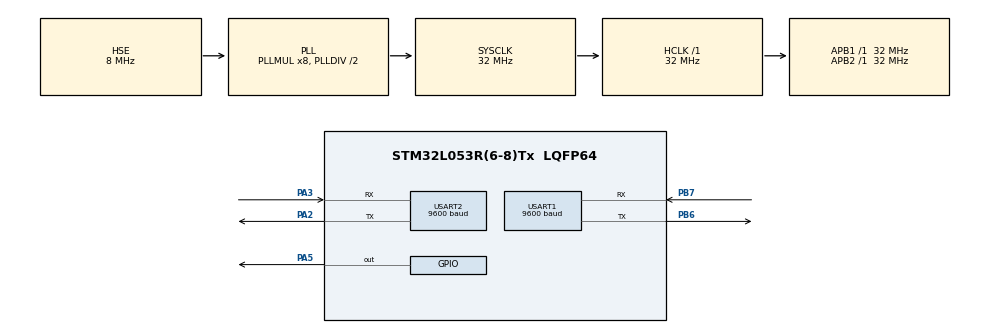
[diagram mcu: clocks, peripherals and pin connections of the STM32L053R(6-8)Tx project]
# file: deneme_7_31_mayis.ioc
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Dma.Request0=USART1_RX
Dma.Request1=USART1_TX
Dma.Request2=USART2_RX
Dma.Request3=USART2_TX
Dma.USART1_RX.0.Direction=DMA_PERIPH_TO_MEMORY
Dma.USART1_RX.0.Instance=DMA1_Channel3
Dma.USART1_RX.0.MemDataAlignment=DMA_MDATAALIGN_BYTE
Dma.USART1_RX.0.MemInc=DMA_MINC_ENABLE
Dma.USART1_RX.0.Mode=DMA_NORMAL
Dma.USART1_RX.0.PeriphDataAlignment=DMA_PDATAALIGN_BYTE
Dma.USART1_RX.0.PeriphInc=DMA_PINC_DISABLE
Dma.USART1_RX.0.Priority=DMA_PRIORITY_HIGH
Dma.USART1_TX.1.Direction=DMA_MEMORY_TO_PERIPH
Dma.USART1_TX.1.Instance=DMA1_Channel2
Dma.USART1_TX.1.MemDataAlignment=DMA_MDATAALIGN_BYTE
Dma.USART1_TX.1.MemInc=DMA_MINC_ENABLE
Dma.USART1_TX.1.Mode=DMA_NORMAL
Dma.USART1_TX.1.PeriphDataAlignment=DMA_PDATAALIGN_BYTE
Dma.USART1_TX.1.PeriphInc=DMA_PINC_DISABLE
Dma.USART1_TX.1.Priority=DMA_PRIORITY_HIGH
Dma.USART2_RX.2.Direction=DMA_PERIPH_TO_MEMORY
Dma.USART2_RX.2.Instance=DMA1_Channel5
Dma.USART2_RX.2.MemDataAlignment=DMA_MDATAALIGN_BYTE
Dma.USART2_RX.2.MemInc=DMA_MINC_ENABLE
Dma.USART2_RX.2.Mode=DMA_NORMAL
Dma.USART2_RX.2.PeriphDataAlignment=DMA_PDATAALIGN_BYTE
Dma.USART2_RX.2.PeriphInc=DMA_PINC_DISABLE
Dma.USART2_RX.2.Priority=DMA_PRIORITY_HIGH
Dma.USART2_TX.3.Direction=DMA_MEMORY_TO_PERIPH
Dma.USART2_TX.3.Instance=DMA1_Channel4
Dma.USART2_TX.3.MemDataAlignment=DMA_MDATAALIGN_BYTE
Dma.USART2_TX.3.MemInc=DMA_MINC_ENABLE
Dma.USART2_TX.3.Mode=DMA_NORMAL
Dma.USART2_TX.3.PeriphDataAlignment=DMA_PDATAALIGN_BYTE
Dma.USART2_TX.3.PeriphInc=DMA_PINC_DISABLE
Dma.USART2_TX.3.Priority=DMA_PRIORITY_HIGH
Mcu.Family=STM32L0
Mcu.Name=STM32L053R(6-8)Tx
Mcu.Package=LQFP64
NVIC.DMA1_Channel2_3_IRQn=true\:0\:0\:false\:false\:true\:false\:true
NVIC.DMA1_Channel4_5_6_7_IRQn=true\:0\:0\:false\:false\:true\:false\:true
NVIC.RCC_CRS_IRQn=true\:0\:0\:false\:false\:true\:true\:false
NVIC.USART1_IRQn=true\:0\:0\:false\:false\:true\:true\:true
NVIC.USART2_IRQn=true\:0\:0\:false\:false\:true\:true\:true
PA13.Mode=Serial_Wire
PA13.Signal=SYS_SWDIO
PA14.Mode=Serial_Wire
PA14.Signal=SYS_SWCLK
PA2.Mode=Asynchronous
PA2.Signal=USART2_TX
PA3.Mode=Asynchronous
PA3.Signal=USART2_RX
PA5.Signal=GPIO_Output
PB6.Mode=Asynchronous
PB6.Signal=USART1_TX
PB7.Mode=Asynchronous
PB7.Signal=USART1_RX
PC14-OSC32_IN.Mode=LSE-External-Oscillator
PC14-OSC32_IN.Signal=RCC_OSC32_IN
PC15-OSC32_OUT.Mode=LSE-External-Oscillator
PC15-OSC32_OUT.Signal=RCC_OSC32_OUT
PH0-OSC_IN.Mode=HSE-External-Oscillator
PH0-OSC_IN.Signal=RCC_OSC_IN
PH1-OSC_OUT.Mode=HSE-External-Oscillator
PH1-OSC_OUT.Signal=RCC_OSC_OUT
ProjectManager.HeapSize=0x200
ProjectManager.StackSize=0x400
ProjectManager.TargetToolchain=STM32CubeIDE
RCC.AHBFreq_Value=32000000
RCC.APB1Freq_Value=32000000
RCC.APB1TimFreq_Value=32000000
RCC.APB2Freq_Value=32000000
RCC.APB2TimFreq_Value=32000000
RCC.HCLKFreq_Value=32000000
RCC.HSE_VALUE=8000000
RCC.HSI16_VALUE=16000000
RCC.HSI48_VALUE=48000000
RCC.HSI_VALUE=16000000
RCC.MSI_VALUE=2097000
RCC.PLLMUL=RCC_PLLMUL_8
RCC.PLLSourceVirtual=RCC_PLLSOURCE_HSE
RCC.SYSCLKFreq_VALUE=32000000
RCC.SYSCLKSource=RCC_SYSCLKSOURCE_PLLCLK
RCC.VCOOutputFreq_Value=64000000
USART1.BaudRate=9600
USART1.VirtualMode-Asynchronous=VM_ASYNC
USART2.BaudRate=9600
USART2.VirtualMode-Asynchronous=VM_ASYNC
board=custom

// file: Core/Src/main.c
/* USER CODE BEGIN Header */
/**
  ******************************************************************************
  * @file           : main.c
  * @brief          : Main program body
  ******************************************************************************
  * @attention
  *
  * <h2><center>&copy; Copyright (c) 2023 STMicroelectronics.
  * All rights reserved.</center></h2>
  *
  * This software component is licensed by ST under BSD 3-Clause license,
  * the "License"; You may not use this file except in compliance with the
  * License. You may obtain a copy of the License at:
  *                        opensource.org/licenses/BSD-3-Clause
  *
  ******************************************************************************
  */
/* USER CODE END Header */
#include "main.h"

UART_HandleTypeDef huart1;
UART_HandleTypeDef huart2;
DMA_HandleTypeDef hdma_usart1_rx;
DMA_HandleTypeDef hdma_usart1_tx;
DMA_HandleTypeDef hdma_usart2_rx;
DMA_HandleTypeDef hdma_usart2_tx;

/* USER CODE BEGIN PV */

#define RxBufferSize 20
uint8_t RxBuffer[RxBufferSize];

/* USER CODE END PV */

void SystemClock_Config(void);
static void MX_GPIO_Init(void);
static void MX_DMA_Init(void);
static void MX_USART1_UART_Init(void);
static void MX_USART2_UART_Init(void);

/* USER CODE BEGIN 0 */

void HAL_UARTEx_RxEventCallback(UART_HandleTypeDef *huart, uint16_t Size)
{
	if(huart->Instance == USART1)
	{
		HAL_UARTEx_ReceiveToIdle_DMA(&huart1, RxBuffer, RxBufferSize);
		__HAL_DMA_DISABLE_IT(&hdma_usart1_rx, DMA_IT_HT);
	}
	if(huart->Instance == USART2)
	{
		HAL_UARTEx_ReceiveToIdle_DMA(&huart2, RxBuffer, RxBufferSize);
		__HAL_DMA_DISABLE_IT(&hdma_usart2_rx, DMA_IT_HT);
	}
}

/* USER CODE END 0 */

int main(void)
{

  /* MCU Configuration--------------------------------------------------------*/

  /* Reset of all peripherals, Initializes the Flash interface and the Systick. */
  HAL_Init();

  /* Configure the system clock */
  SystemClock_Config();

  /* Initialize all configured peripherals */
  MX_GPIO_Init();
  MX_DMA_Init();
  MX_USART1_UART_Init();
  MX_USART2_UART_Init();
  /* USER CODE BEGIN 2 */

  HAL_UARTEx_ReceiveToIdle_DMA(&huart1, RxBuffer, RxBufferSize);
  __HAL_DMA_DISABLE_IT(&hdma_usart1_rx, DMA_IT_HT);

  HAL_UARTEx_ReceiveToIdle_DMA(&huart2, RxBuffer, RxBufferSize);
  __HAL_DMA_DISABLE_IT(&hdma_usart2_rx, DMA_IT_HT);

  /* USER CODE END 2 */

  /* Infinite loop */
  while (1)
  {

  }
}

void SystemClock_Config(void)
{
  RCC_OscInitTypeDef RCC_OscInitStruct = {0};
  RCC_ClkInitTypeDef RCC_ClkInitStruct = {0};
  RCC_PeriphCLKInitTypeDef PeriphClkInit = {0};

  /** Configure the main internal regulator output voltage
  */
  __HAL_PWR_VOLTAGESCALING_CONFIG(PWR_REGULATOR_VOLTAGE_SCALE1);
  /** Initializes the RCC Oscillators according to the specified parameters
  * in the RCC_OscInitTypeDef structure.
  */
  RCC_OscInitStruct.OscillatorType = RCC_OSCILLATORTYPE_HSE;
  RCC_OscInitStruct.HSEState = RCC_HSE_ON;
  RCC_OscInitStruct.PLL.PLLState = RCC_PLL_ON;
  RCC_OscInitStruct.PLL.PLLSource = RCC_PLLSOURCE_HSE;
  RCC_OscInitStruct.PLL.PLLMUL = RCC_PLLMUL_8;
  RCC_OscInitStruct.PLL.PLLDIV = RCC_PLLDIV_2;
  if (HAL_RCC_OscConfig(&RCC_OscInitStruct) != HAL_OK)
  {
    Error_Handler();
  }
  /** Initializes the CPU, AHB and APB buses clocks
  */
  RCC_ClkInitStruct.ClockType = RCC_CLOCKTYPE_HCLK|RCC_CLOCKTYPE_SYSCLK
                              |RCC_CLOCKTYPE_PCLK1|RCC_CLOCKTYPE_PCLK2;
  RCC_ClkInitStruct.SYSCLKSource = RCC_SYSCLKSOURCE_PLLCLK;
  RCC_ClkInitStruct.AHBCLKDivider = RCC_SYSCLK_DIV1;
  RCC_ClkInitStruct.APB1CLKDivider = RCC_HCLK_DIV1;
  RCC_ClkInitStruct.APB2CLKDivider = RCC_HCLK_DIV1;

  if (HAL_RCC_ClockConfig(&RCC_ClkInitStruct, FLASH_LATENCY_1) != HAL_OK)
  {
    Error_Handler();
  }
  PeriphClkInit.PeriphClockSelection = RCC_PERIPHCLK_USART1|RCC_PERIPHCLK_USART2;
  PeriphClkInit.Usart1ClockSelection = RCC_USART1CLKSOURCE_PCLK2;
  PeriphClkInit.Usart2ClockSelection = RCC_USART2CLKSOURCE_PCLK1;
  if (HAL_RCCEx_PeriphCLKConfig(&PeriphClkInit) != HAL_OK)
  {
    Error_Handler();
  }
}

static void MX_USART1_UART_Init(void)
{

  huart1.Instance = USART1;
  huart1.Init.BaudRate = 9600;
  huart1.Init.WordLength = UART_WORDLENGTH_8B;
  huart1.Init.StopBits = UART_STOPBITS_1;
  huart1.Init.Parity = UART_PARITY_NONE;
  huart1.Init.Mode = UART_MODE_TX_RX;
  huart1.Init.HwFlowCtl = UART_HWCONTROL_NONE;
  huart1.Init.OverSampling = UART_OVERSAMPLING_16;
  huart1.Init.OneBitSampling = UART_ONE_BIT_SAMPLE_DISABLE;
  huart1.AdvancedInit.AdvFeatureInit = UART_ADVFEATURE_NO_INIT;
  if (HAL_UART_Init(&huart1) != HAL_OK)
  {
    Error_Handler();
  }

}

static void MX_USART2_UART_Init(void)
{

  huart2.Instance = USART2;
  huart2.Init.BaudRate = 9600;
  huart2.Init.WordLength = UART_WORDLENGTH_8B;
  huart2.Init.StopBits = UART_STOPBITS_1;
  huart2.Init.Parity = UART_PARITY_NONE;
  huart2.Init.Mode = UART_MODE_TX_RX;
  huart2.Init.HwFlowCtl = UART_HWCONTROL_NONE;
  huart2.Init.OverSampling = UART_OVERSAMPLING_16;
  huart2.Init.OneBitSampling = UART_ONE_BIT_SAMPLE_DISABLE;
  huart2.AdvancedInit.AdvFeatureInit = UART_ADVFEATURE_NO_INIT;
  if (HAL_UART_Init(&huart2) != HAL_OK)
  {
    Error_Handler();
  }

}

static void MX_DMA_Init(void)
{

  /* DMA controller clock enable */
  __HAL_RCC_DMA1_CLK_ENABLE();

  /* DMA interrupt init */
  /* DMA1_Channel2_3_IRQn interrupt configuration */
  HAL_NVIC_SetPriority(DMA1_Channel2_3_IRQn, 0, 0);
  HAL_NVIC_EnableIRQ(DMA1_Channel2_3_IRQn);
  /* DMA1_Channel4_5_6_7_IRQn interrupt configuration */
  HAL_NVIC_SetPriority(DMA1_Channel4_5_6_7_IRQn, 0, 0);
  HAL_NVIC_EnableIRQ(DMA1_Channel4_5_6_7_IRQn);

}

static void MX_GPIO_Init(void)
{
  GPIO_InitTypeDef GPIO_InitStruct = {0};

  /* GPIO Ports Clock Enable */
  __HAL_RCC_GPIOC_CLK_ENABLE();
  __HAL_RCC_GPIOH_CLK_ENABLE();
  __HAL_RCC_GPIOA_CLK_ENABLE();
  __HAL_RCC_GPIOB_CLK_ENABLE();

  /*Configure GPIO pin Output Level */
  HAL_GPIO_WritePin(GPIOA, GPIO_PIN_5, GPIO_PIN_RESET);

  /*Configure GPIO pin : PA5 */
  GPIO_InitStruct.Pin = GPIO_PIN_5;
  GPIO_InitStruct.Mode = GPIO_MODE_OUTPUT_PP;
  GPIO_InitStruct.Pull = GPIO_NOPULL;
  GPIO_InitStruct.Speed = GPIO_SPEED_FREQ_LOW;
  HAL_GPIO_Init(GPIOA, &GPIO_InitStruct);

}

void Error_Handler(void)
{
  __disable_irq();
  while (1)
  {
  }
}

/************************ (C) COPYRIGHT STMicroelectronics *****END OF FILE****/
